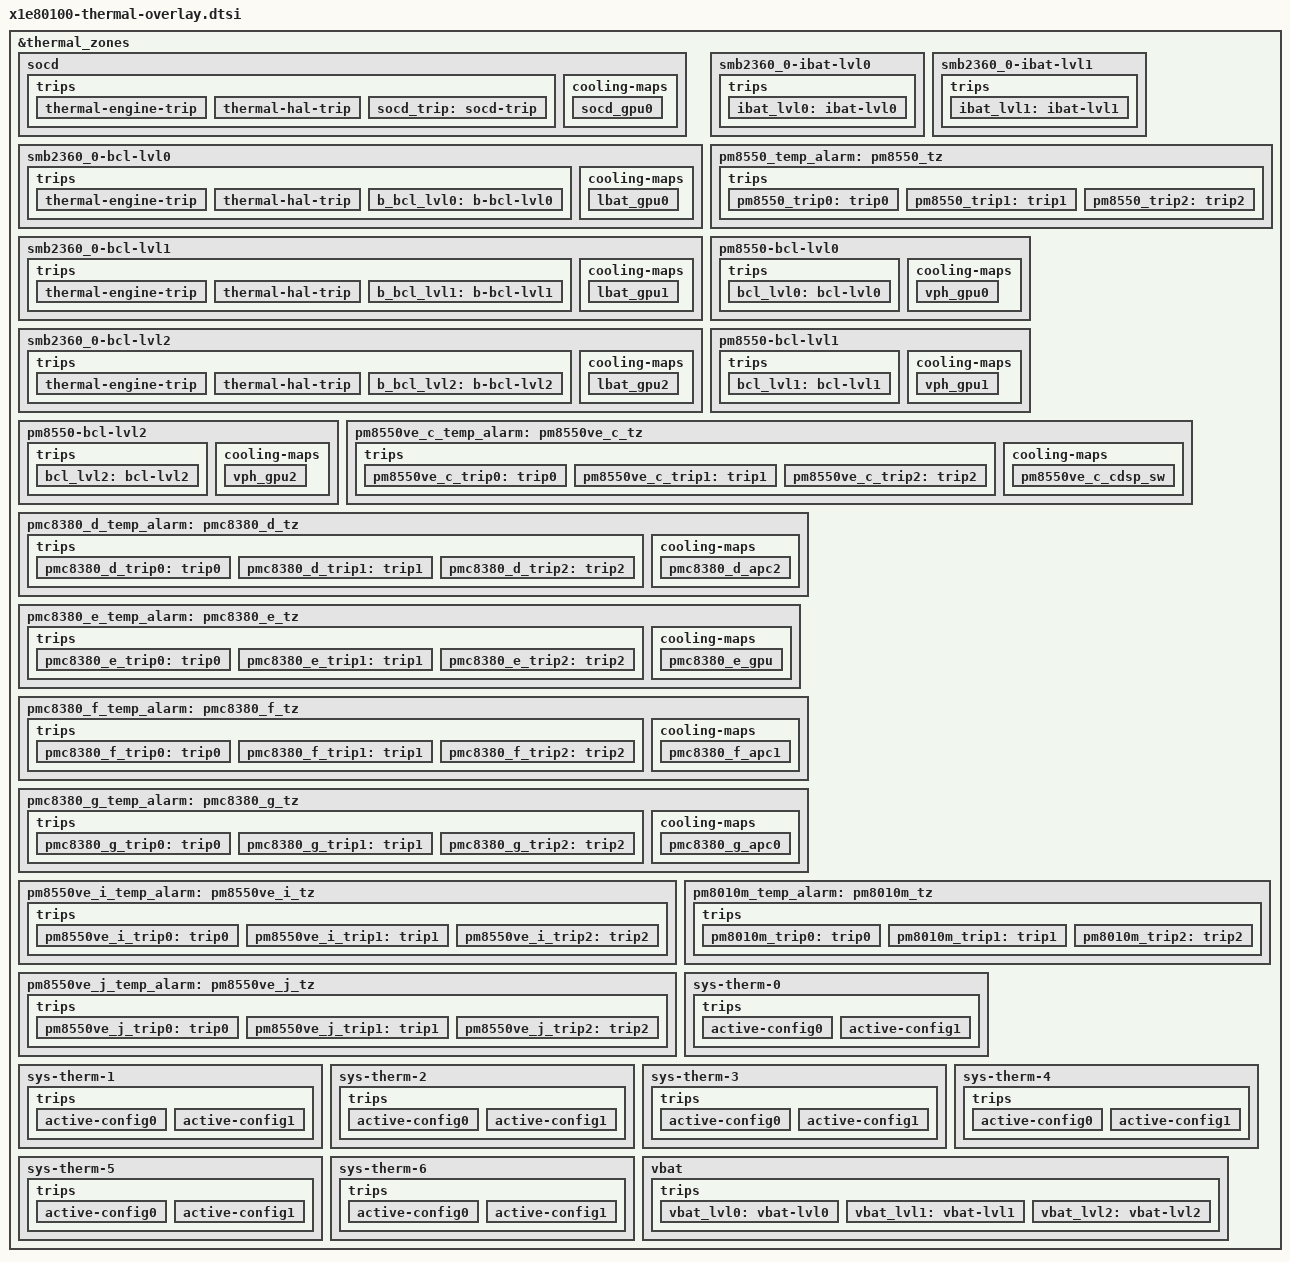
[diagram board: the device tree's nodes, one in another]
// SPDX-License-Identifier: BSD-3-Clause
/*
 * Copyright (c) Qualcomm Technologies, Inc. and/or its subsidiaries.
 */

&thermal_zones {
	socd {
		polling-delay-passive = <100>;
		polling-delay = <0>;
		thermal-sensors = <&bcl_soc>;

		trips {
			thermal-engine-trip {
				temperature = <100>;
				hysteresis = <0>;
				type = "passive";
			};

			thermal-hal-trip {
				temperature = <100>;
				hysteresis = <0>;
				type = "passive";
			};

			socd_trip: socd-trip {
				temperature = <90>;
				hysteresis = <0>;
				type = "passive";
			};
		};

		cooling-maps {
			socd_gpu0 {
				trip = <&socd_trip>;
				cooling-device = <&APC1_APC2_MX_CX_PAUSE 0 1>,
						 <&cdsp_sw 0 4>,
						 <&msm_gpu 0 4>;
			};
		};
	};

	smb2360_0-bcl-lvl0 {
		polling-delay-passive = <100>;
		polling-delay = <0>;
		thermal-sensors = <&smb2360_0_bcl 5>;

		trips {
			thermal-engine-trip {
				temperature = <100>;
				hysteresis = <0>;
				type = "passive";
			};

			thermal-hal-trip {
				temperature = <100>;
				hysteresis = <0>;
				type = "passive";
			};

			b_bcl_lvl0: b-bcl-lvl0 {
				temperature = <1>;
				hysteresis = <0>;
				type = "passive";
			};
		};

		cooling-maps {
			lbat_gpu0 {
				trip = <&b_bcl_lvl0>;
				cooling-device = <&msm_gpu 1 1>,
						 <&cdsp_sw 0 4>;
			};
		};
	};

	smb2360_0-bcl-lvl1 {
		polling-delay-passive = <100>;
		polling-delay = <0>;
		thermal-sensors = <&smb2360_0_bcl 6>;

		trips {
			thermal-engine-trip {
				temperature = <100>;
				hysteresis = <0>;
				type = "passive";
			};

			thermal-hal-trip {
				temperature = <100>;
				hysteresis = <0>;
				type = "passive";
			};

			b_bcl_lvl1: b-bcl-lvl1 {
				temperature = <1>;
				hysteresis = <0>;
				type = "passive";
			};
		};

		cooling-maps {
			lbat_gpu1 {
				trip = <&b_bcl_lvl1>;
				cooling-device = <&msm_gpu 2 2>;
			};
		};
	};

	smb2360_0-bcl-lvl2 {
		polling-delay-passive = <100>;
		polling-delay = <0>;
		thermal-sensors = <&smb2360_0_bcl 7>;

		trips {
			thermal-engine-trip {
				temperature = <100>;
				hysteresis = <0>;
				type = "passive";
			};

			thermal-hal-trip {
				temperature = <100>;
				hysteresis = <0>;
				type = "passive";
			};

			b_bcl_lvl2: b-bcl-lvl2 {
				temperature = <1>;
				hysteresis = <0>;
				type = "passive";
			};
		};

		cooling-maps {
			lbat_gpu2 {
				trip = <&b_bcl_lvl2>;
				cooling-device = <&msm_gpu 3 3>;
			};
		};
	};

	smb2360_0-ibat-lvl0 {
		polling-delay-passive = <0>;
		polling-delay = <0>;
		thermal-sensors = <&smb2360_0_bcl 0>;

		trips {
			ibat_lvl0:ibat-lvl0 {
				temperature = <13500>;
				hysteresis = <200>;
				type = "passive";
			};
		};
	};

	smb2360_0-ibat-lvl1 {
		polling-delay-passive = <0>;
		polling-delay = <0>;
		thermal-sensors = <&smb2360_0_bcl 1>;

		trips {
			ibat_lvl1:ibat-lvl1 {
				temperature = <15000>;
				hysteresis = <200>;
				type = "passive";
			};
		};
	};

	pm8550_temp_alarm: pm8550_tz {
		polling-delay-passive = <100>;
		thermal-sensors = <&pm8550_tz>;

		trips {
			pm8550_trip0: trip0 {
				temperature = <95000>;
				hysteresis = <0>;
				type = "passive";
			};

			pm8550_trip1: trip1 {
				temperature = <115000>;
				hysteresis = <0>;
				type = "hot";
			};

			pm8550_trip2: trip2 {
				temperature = <145000>;
				hysteresis = <0>;
				type = "critical";
			};
		};
	};

	pm8550-bcl-lvl0 {
		polling-delay-passive = <100>;
		thermal-governor = "step_wise";
		thermal-sensors = <&pm8550_bcl 5>;

		trips {
			bcl_lvl0: bcl-lvl0 {
				temperature = <1>;
				hysteresis = <0>;
				type = "passive";
			};
		};

		cooling-maps {

			vph_gpu0 {
				trip = <&bcl_lvl0>;
				cooling-device = <&msm_gpu 1 1>;
			};
		};
	};

	pm8550-bcl-lvl1 {
		polling-delay-passive = <100>;
		thermal-governor = "step_wise";
		thermal-sensors = <&pm8550_bcl 6>;

		trips {
			bcl_lvl1: bcl-lvl1 {
				temperature = <1>;
				hysteresis = <0>;
				type = "passive";
			};
		};

		cooling-maps {
			vph_gpu1 {
				trip = <&bcl_lvl1>;
				cooling-device = <&msm_gpu 2 2>;
			};
		};
	};

	pm8550-bcl-lvl2 {
		polling-delay-passive = <100>;
		thermal-governor = "step_wise";
		thermal-sensors = <&pm8550_bcl 7>;

		trips {
			bcl_lvl2: bcl-lvl2 {
				temperature = <1>;
				hysteresis = <0>;
				type = "passive";
			};
		};

		cooling-maps {
			vph_gpu2 {
				trip = <&bcl_lvl2>;
				cooling-device = <&msm_gpu 3 3>;
			};
		};
	};

	pm8550ve_c_temp_alarm: pm8550ve_c_tz {
		polling-delay-passive = <100>;
		thermal-sensors = <&pm8550ve_c_tz>;

		trips {
			pm8550ve_c_trip0: trip0 {
				temperature = <95000>;
				hysteresis = <0>;
				type = "passive";
			};

			pm8550ve_c_trip1: trip1 {
				temperature = <115000>;
				hysteresis = <0>;
				type = "hot";
			};

			pm8550ve_c_trip2: trip2 {
				temperature = <145000>;
				hysteresis = <0>;
				type = "critical";
			};
		};

		cooling-maps {
			pm8550ve_c_cdsp_sw {
				trip = <&pm8550ve_c_trip0>;
				cooling-device = <&cdsp_sw 0 4>;
			};
		};
	};

	pmc8380_d_temp_alarm: pmc8380_d_tz {
		polling-delay-passive = <100>;
		thermal-sensors = <&pmc8380_d_tz>;

		trips {
			pmc8380_d_trip0: trip0 {
				temperature = <95000>;
				hysteresis = <0>;
				type = "passive";
			};

			pmc8380_d_trip1: trip1 {
				temperature = <115000>;
				hysteresis = <0>;
				type = "hot";
			};

			pmc8380_d_trip2: trip2 {
				temperature = <145000>;
				hysteresis = <0>;
				type = "critical";
			};
		};

		cooling-maps {
			pmc8380_d_apc2 {
				trip = <&pmc8380_d_trip0>;
				cooling-device = <&APC2_MX_CX_PAUSE 1 1>;
			};
		};
	};

	pmc8380_e_temp_alarm: pmc8380_e_tz {
		polling-delay-passive = <100>;
		thermal-sensors = <&pmc8380_e_tz>;

		trips {
			pmc8380_e_trip0: trip0 {
				temperature = <95000>;
				hysteresis = <0>;
				type = "passive";
			};

			pmc8380_e_trip1: trip1 {
				temperature = <115000>;
				hysteresis = <0>;
				type = "hot";
			};

			pmc8380_e_trip2: trip2 {
				temperature = <145000>;
				hysteresis = <0>;
				type = "critical";
			};
		};

		cooling-maps {
			pmc8380_e_gpu {
				trip = <&pmc8380_e_trip0>;
				cooling-device = <&msm_gpu 1 1>;
			};
		};
	};

	pmc8380_f_temp_alarm: pmc8380_f_tz {
		polling-delay-passive = <100>;
		thermal-sensors = <&pmc8380_f_tz>;

		trips {
			pmc8380_f_trip0: trip0 {
				temperature = <95000>;
				hysteresis = <0>;
				type = "passive";
			};

			pmc8380_f_trip1: trip1 {
				temperature = <115000>;
				hysteresis = <0>;
				type = "hot";
			};

			pmc8380_f_trip2: trip2 {
				temperature = <145000>;
				hysteresis = <0>;
				type = "critical";
			};
		};

		cooling-maps {
			pmc8380_f_apc1 {
				trip = <&pmc8380_f_trip0>;
				cooling-device = <&APC1_MX_CX_PAUSE 1 1>;
			};
		};
	};

	pmc8380_g_temp_alarm: pmc8380_g_tz {
		polling-delay-passive = <100>;
		thermal-sensors = <&pmc8380_g_tz>;

		trips {
			pmc8380_g_trip0: trip0 {
				temperature = <95000>;
				hysteresis = <0>;
				type = "passive";
			};

			pmc8380_g_trip1: trip1 {
				temperature = <115000>;
				hysteresis = <0>;
				type = "hot";
			};

			pmc8380_g_trip2: trip2 {
				temperature = <145000>;
				hysteresis = <0>;
				type = "critical";
			};
		};

		cooling-maps {
			pmc8380_g_apc0 {
				trip = <&pmc8380_g_trip0>;
				cooling-device = <&APC0_MX_CX_PAUSE 1 1>;
			};
		};
	};

	pm8550ve_i_temp_alarm: pm8550ve_i_tz {
		polling-delay-passive = <100>;
		thermal-sensors = <&pm8550ve_i_tz>;

		trips {
			pm8550ve_i_trip0: trip0 {
				temperature = <95000>;
				hysteresis = <0>;
				type = "passive";
			};

			pm8550ve_i_trip1: trip1 {
				temperature = <115000>;
				hysteresis = <0>;
				type = "hot";
			};

			pm8550ve_i_trip2: trip2 {
				temperature = <145000>;
				hysteresis = <0>;
				type = "critical";
			};
		};
	};

	pm8550ve_j_temp_alarm: pm8550ve_j_tz {
		polling-delay-passive = <100>;
		thermal-sensors = <&pm8550ve_j_tz>;

		trips {
			pm8550ve_j_trip0: trip0 {
				temperature = <95000>;
				hysteresis = <0>;
				type = "passive";
			};

			pm8550ve_j_trip1: trip1 {
				temperature = <115000>;
				hysteresis = <0>;
				type = "hot";
			};

			pm8550ve_j_trip2: trip2 {
				temperature = <145000>;
				hysteresis = <0>;
				type = "critical";
			};
		};
	};

	pm8010m_temp_alarm: pm8010m_tz {
		polling-delay-passive = <100>;
		thermal-sensors = <&pm8010m_tz>;

		trips {
			pm8010m_trip0: trip0 {
				temperature = <95000>;
				hysteresis = <0>;
				type = "passive";
			};

			pm8010m_trip1: trip1 {
				temperature = <115000>;
				hysteresis = <0>;
				type = "hot";
			};

			pm8010m_trip2: trip2 {
				temperature = <145000>;
				hysteresis = <0>;
				type = "critical";
			};
		};
	};

	sys-therm-0 {
		polling-delay-passive = <0>;
		polling-delay = <0>;
		thermal-sensors = <&pmk8550_vadc PM8550_ADC5_GEN3_AMUX1_GPIO3_100K_PU>;
		trips {
			active-config0 {
				temperature = <125000>;
				hysteresis = <1000>;
				type = "passive";
			};

			active-config1 {
				temperature = <125000>;
				hysteresis = <1000>;
				type = "passive";
			};
		};
	};

	sys-therm-1 {
		polling-delay-passive = <0>;
		polling-delay = <0>;
		thermal-sensors = <&pmk8550_vadc PM8550_ADC5_GEN3_AMUX2_GPIO4_100K_PU>;
		trips {
			active-config0 {
				temperature = <125000>;
				hysteresis = <1000>;
				type = "passive";
			};

			active-config1 {
				temperature = <125000>;
				hysteresis = <1000>;
				type = "passive";
			};
		};
	};

	sys-therm-2 {
		polling-delay-passive = <0>;
		polling-delay = <0>;
		thermal-sensors = <&pmk8550_vadc PM8550_ADC5_GEN3_AMUX_THM1_100K_PU>;
		trips {
			active-config0 {
				temperature = <125000>;
				hysteresis = <1000>;
				type = "passive";
			};

			active-config1 {
				temperature = <125000>;
				hysteresis = <1000>;
				type = "passive";
			};
		};
	};

	sys-therm-3 {
		polling-delay-passive = <0>;
		polling-delay = <0>;
		thermal-sensors = <&pmk8550_vadc PM8550_ADC5_GEN3_AMUX_THM2_100K_PU>;
		trips {
			active-config0 {
				temperature = <125000>;
				hysteresis = <1000>;
				type = "passive";
			};

			active-config1 {
				temperature = <125000>;
				hysteresis = <1000>;
				type = "passive";
			};
		};
	};

	sys-therm-4 {
		polling-delay-passive = <0>;
		polling-delay = <0>;
		thermal-sensors = <&pmk8550_vadc PM8550_ADC5_GEN3_AMUX_THM3_100K_PU>;
		trips {
			active-config0 {
				temperature = <125000>;
				hysteresis = <1000>;
				type = "passive";
			};

			active-config1 {
				temperature = <125000>;
				hysteresis = <1000>;
				type = "passive";
			};
		};
	};

	sys-therm-5 {
		polling-delay-passive = <0>;
		polling-delay = <0>;
		thermal-sensors = <&pmk8550_vadc PM8550_ADC5_GEN3_AMUX_THM4_100K_PU>;
		trips {
			active-config0 {
				temperature = <125000>;
				hysteresis = <1000>;
				type = "passive";
			};

			active-config1 {
				temperature = <125000>;
				hysteresis = <1000>;
				type = "passive";
			};
		};
	};

	sys-therm-6 {
		polling-delay-passive = <0>;
		polling-delay = <0>;
		thermal-sensors = <&pmk8550_vadc PM8550_ADC5_GEN3_AMUX_THM5_100K_PU>;
		trips {
			active-config0 {
				temperature = <125000>;
				hysteresis = <1000>;
				type = "passive";
			};

			active-config1 {
				temperature = <125000>;
				hysteresis = <1000>;
				type = "passive";
			};
		};
	};

	vbat {
		polling-delay-passive = <0>;
		polling-delay = <0>;
		thermal-sensors = <&smb2360_0_bcl 2>;

		trips {
			vbat_lvl0:vbat-lvl0 {
				temperature = <2800>;
				hysteresis = <100>;
				type = "passive";
			};

			vbat_lvl1:vbat-lvl1 {
				temperature = <2600>;
				hysteresis = <100>;
				type = "passive";
			};

			vbat_lvl2:vbat-lvl2 {
				temperature = <2300>;
				hysteresis = <100>;
				type = "passive";
			};
		};
	};
};
